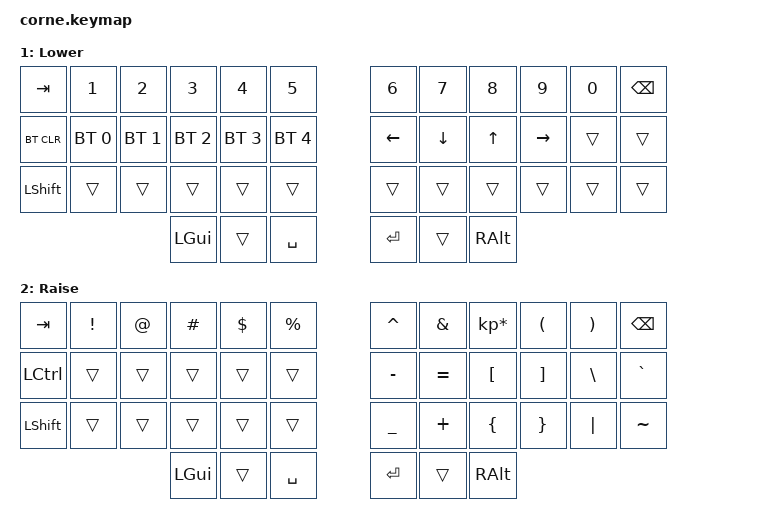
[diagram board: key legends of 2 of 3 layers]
/*
 * Copyright (c) 2020 The ZMK Contributors
 *
 * SPDX-License-Identifier: MIT
 */

#include <behaviors.dtsi>
#include <dt-bindings/zmk/keys.h>
#include <dt-bindings/zmk/bt.h>

/ {
        behaviors {
                hm: homerow_mods {
                        compatible = "zmk,behavior-hold-tap";
                        label = "HOMEROW_MODS";
                        #binding-cells = <2>;
                        tapping-term-ms = <200>;
                        quick-tap-ms = <0>;
                        flavor = "tap-preferred";
                        bindings = <&kp>, <&kp>;
                };
        };

        keymap {
                compatible = "zmk,keymap";

                default_layer {
// -----------------------------------------------------------------------------------------
// |  Q    |  W  |  E   |  R   |  T   |   |  Y   |  U    |  I    |  O   |   P   |
// |  A    |  S  |  D   |  F   |  G   |   |  H   |  J    |  K    |  L   |   ;   |
// |  Z    |  X  |  C   |  V   |  B   |   |  N   |  M    |  ,    |  .   |   /   |
//               | NAV  | NUM  | SYM  |   | SPC  | FUN   | MED   |
                        display-name = "Base";
                        bindings = <
   &kp Q       &kp W      &kp E       &kp R       &kp T          &kp Y    &kp U        &kp I        &kp O       &kp P    
   &hm LGUI A  &hm LALT S &hm LCTRL D &hm LSHFT F &kp G          &kp H    &hm RSHFT J  &hm RCTRL K  &hm RALT L  &hm RGUI SEMI
   &kp Z       &kp X      &kp C       &kp V       &kp B          &kp N    &kp M        &kp COMMA    &kp DOT     &kp FSLH 
                          &lt 1 TAB   &lt 2 BSPC  &lt 3 ESC      &lt 4 SPACE &lt 5 RET &lt 6 DEL
                        >;
                };
                lower_layer {
// -----------------------------------------------------------------------------------------
// |  TAB |  1  |  2  |  3  |  4  |  5  |   |  6  |  7  |  8  |  9  |  0  | BKSP |
// | BTCLR| BT1 | BT2 | BT3 | BT4 | BT5 |   | LFT | DWN |  UP | RGT |     |      |
// | SHFT |     |     |     |     |     |   |     |     |     |     |     |      |
//                    | GUI |     | SPC |   | ENT |     | ALT |
                        display-name = "Lower";
                        bindings = <
   &kp TAB    &kp N1       &kp N2       &kp N3       &kp N4       &kp N5         &kp N6   &kp N7   &kp N8 &kp N9    &kp N0 &kp BSPC
   &bt BT_CLR &bt BT_SEL 0 &bt BT_SEL 1 &bt BT_SEL 2 &bt BT_SEL 3 &bt BT_SEL 4   &kp LEFT &kp DOWN &kp UP &kp RIGHT &trans &trans
   &kp LSHFT  &trans       &trans       &trans       &trans       &trans         &trans   &trans   &trans &trans    &trans &trans
                          	        &kp LGUI     &trans       &kp SPACE      &kp RET  &trans   &kp RALT
                        >;
                };

                raise_layer {
// -----------------------------------------------------------------------------------------
// |  TAB |  !  |  @  |  #  |  $  |  %  |   |  ^  |  &  |  *  |  (  |  )  | BKSP |
// | CTRL |     |     |     |     |     |   |  -  |  =  |  [  |  ]  |  \  |  `   |
// | SHFT |     |     |     |     |     |   |  _  |  +  |  {  |  }  | "|" |  ~   |
//                    | GUI |     | SPC |   | ENT |     | ALT |
                        display-name = "Raise";
                        bindings = <
   &kp  TAB  &kp EXCL &kp AT &kp HASH &kp DLLR &kp PRCNT   &kp CARET &kp AMPS  &kp KP_MULTIPLY &kp LPAR &kp RPAR &kp BSPC
   &kp LCTRL &trans   &trans &trans   &trans   &trans      &kp MINUS &kp EQUAL &kp LBKT        &kp RBKT &kp BSLH &kp GRAVE
   &kp LSHFT &trans   &trans &trans   &trans   &trans      &kp UNDER &kp PLUS  &kp LBRC        &kp RBRC &kp PIPE &kp TILDE
                    	     &kp LGUI &trans   &kp SPACE   &kp RET   &trans    &kp RALT
                        >;
                };

                extra_1 {
                        status = "reserved";
                };

                extra_2 {
                        status = "reserved";
                };

                extra_3 {
                        status = "reserved";
                };
        };
};
